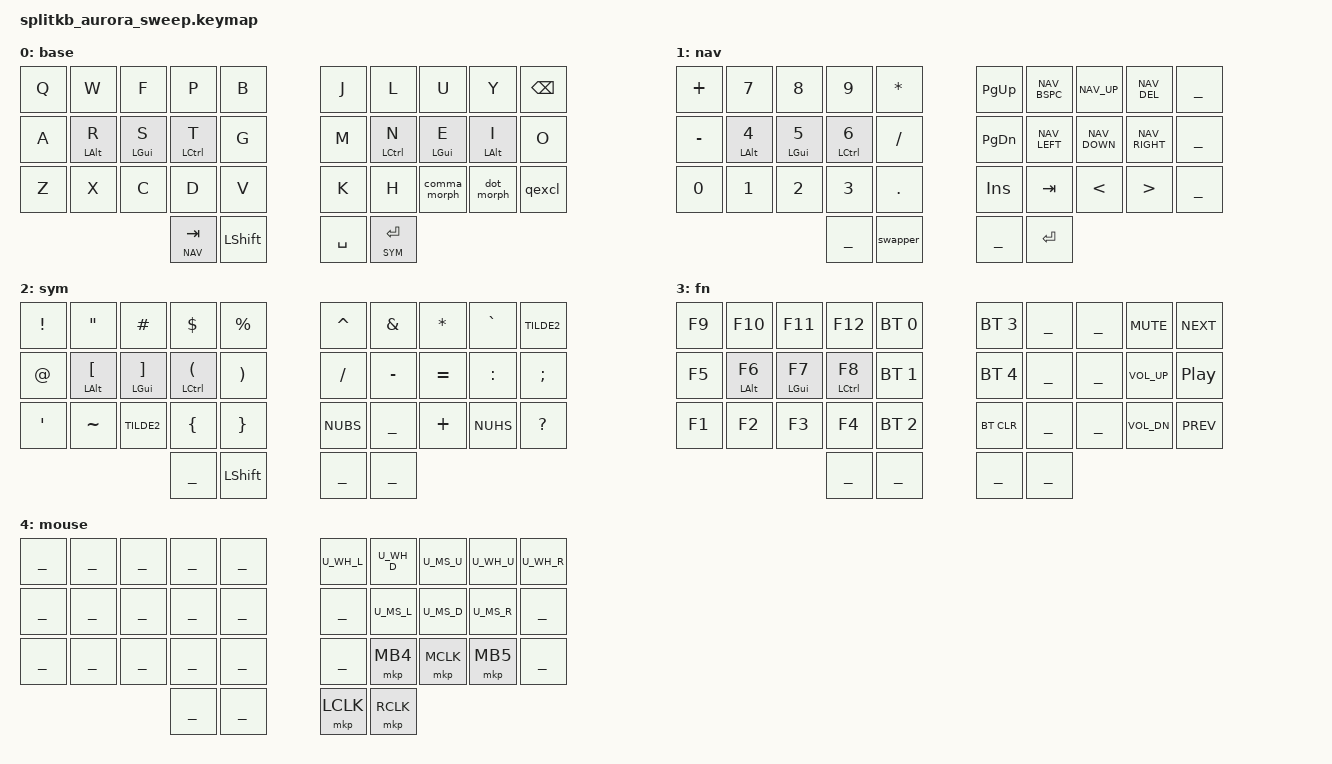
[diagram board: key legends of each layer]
/* source key position labels */
#include "zmk-helpers/key-labels/34.h"

/* source the main keymap */
#include "base.keymap"
ZMK_CONDITIONAL_LAYER(NAV SYM, FN)  // SYM + NAV --> FN

ZMK_LAYER(base,
//╭─────────────┬─────────────┬─────────────┬─────────────┬─────────────╮ ╭─────────────┬─────────────┬─────────────┬─────────────┬─────────────╮
    &kp Q         &kp W         &kp F         &kp P         &kp B           &kp J         &kp L         &kp U         &kp Y         &kp BSPC
//├─────────────┼─────────────┼─────────────┼─────────────┼─────────────┤ ├─────────────┼─────────────┼─────────────┼─────────────┼─────────────┤
    &kp A         &hml LALT R   &hml LGUI S   &hml LCTRL T  &kp G           &kp M         &hmr LCTRL N  &hmr LGUI E   &hmr LALT I   &kp O
//├─────────────┼─────────────┼─────────────┼─────────────┼─────────────┤ ├─────────────┼─────────────┼─────────────┼─────────────┼─────────────┤
    &kp Z         &kp X         &kp C         &kp D         &kp V           &kp K         &kp H         &comma_morph  &dot_morph    &qexcl
//╰─────────────┼─────────────┴─────────────┼─────────────┼─────────────┤ ├─────────────┼─────────────┼─────────────┴───────────────────────────╯
                                              &lt NAV TAB   &kp LSHIFT      &kp SPACE     &lt SYM RET
//                                          ╰─────────────┴─────────────╯ ╰─────────────┴─────────────╯
)

ZMK_LAYER(nav,
//╭─────────────┬─────────────┬─────────────┬─────────────┬─────────────╮ ╭─────────────┬─────────────┬─────────────┬─────────────┬─────────────╮
    &kp PLUS      &kp N7        &kp N8        &kp N9        &kp ASTRK       &kp PG_UP     NAV_BSPC      NAV_UP        NAV_DEL       ___
//├─────────────┼─────────────┼─────────────┼─────────────┼─────────────┤ ├─────────────┼─────────────┼─────────────┼─────────────┼─────────────┤
    &kp MINUS     &hml LALT N4  &hml LGUI N5  &hml LCTRL N6 &kp FSLH        &kp PG_DN     NAV_LEFT      NAV_DOWN      NAV_RIGHT     ___
//├─────────────┼─────────────┼─────────────┼─────────────┼─────────────┤ ├─────────────┼─────────────┼─────────────┼─────────────┼─────────────┤
    &kp N0        &kp N1        &kp N2        &kp N3        &kp DOT         &kp INS       &kp TAB       &kp LT        &kp GT        ___
//╰─────────────┼─────────────┴─────────────┼─────────────┼─────────────┤ ├─────────────┼─────────────┼─────────────┴───────────────────────────╯
                                              ___           &swapper        ___           &kp RET
//                                          ╰─────────────┴─────────────╯ ╰─────────────┴─────────────╯
)

ZMK_LAYER(sym,
//╭─────────────┬─────────────┬─────────────┬─────────────┬─────────────╮ ╭─────────────┬─────────────┬─────────────┬─────────────┬─────────────╮
    &kp EXCL      &kp DQT       &kp HASH      &kp DLLR      &kp PRCNT       &kp CARET     &kp AMPS      &kp ASTRK     &kp GRAVE     &kp TILDE2
//├─────────────┼─────────────┼─────────────┼─────────────┼─────────────┤ ├─────────────┼─────────────┼─────────────┼─────────────┼─────────────┤
    &kp AT        &hml LALT LBKT &hml LGUI RBKT &hml LCTRL LPAR &kp RPAR    &kp FSLH      &kp MINUS     &kp EQUAL     &kp COLON     &kp SEMI
//├─────────────┼─────────────┼─────────────┼─────────────┼─────────────┤ ├─────────────┼─────────────┼─────────────┼─────────────┼─────────────┤
    &kp SQT       &kp TILDE      &kp TILDE2   &kp LBRC      &kp RBRC        &kp NUBS      &kp UNDER     &kp PLUS      &kp NUHS      &kp QMARK
//╰─────────────┼─────────────┴─────────────┼─────────────┼─────────────┤ ├─────────────┼─────────────┼─────────────┴───────────────────────────╯
                                              ___           &kp LSHIFT      ___           ___
//                                          ╰─────────────┴─────────────╯ ╰─────────────┴─────────────╯
)

ZMK_LAYER(fn,
//╭─────────────┬─────────────┬─────────────┬─────────────┬─────────────╮ ╭─────────────┬─────────────┬─────────────┬─────────────┬─────────────╮
   &kp F9        &kp F10       &kp F11       &kp F12       &bt BT_SEL 0     &bt BT_SEL 3  ___           ___           &kp C_MUTE    &kp C_NEXT
//├─────────────┼─────────────┼─────────────┼─────────────┼─────────────┤ ├─────────────┼─────────────┼─────────────┼─────────────┼─────────────┤
   &kp F5        &hml LALT F6  &hml LGUI F7  &hml LCTRL F8 &bt BT_SEL 1     &bt BT_SEL 4  ___           ___           &kp C_VOL_UP  &kp C_PP
//├─────────────┼─────────────┼─────────────┼─────────────┼─────────────┤ ├─────────────┼─────────────┼─────────────┼─────────────┼─────────────┤
   &kp F1        &kp F2        &kp F3        &kp F4        &bt BT_SEL 2     &bt BT_CLR    ___           ___           &kp C_VOL_DN  &kp C_PREV
//╰─────────────┼─────────────┴─────────────┼─────────────┼─────────────┤ ├─────────────┼─────────────┼─────────────┴───────────────────────────╯
                                              ___           ___             ___           ___
//                                          ╰─────────────┴─────────────╯ ╰─────────────┴─────────────╯
)

ZMK_LAYER(mouse,
//╭─────────────┬─────────────┬─────────────┬─────────────┬─────────────╮ ╭─────────────┬─────────────┬─────────────┬─────────────┬─────────────╮
    ___           ___           ___           ___           ___             U_WH_L        U_WH_D        U_MS_U         U_WH_U       U_WH_R
//├─────────────┼─────────────┼─────────────┼─────────────┼─────────────┤ ├─────────────┼─────────────┼─────────────┼─────────────┼─────────────┤
    ___           ___           ___           ___           ___             ___           U_MS_L        U_MS_D         U_MS_R       ___
//├─────────────┼─────────────┼─────────────┼─────────────┼─────────────┤ ├─────────────┼─────────────┼─────────────┼─────────────┼─────────────┤
    ___           ___           ___           ___           ___             ___           &mkp MB4      &mkp MCLK      &mkp MB5     ___
//╰─────────────┼─────────────┴─────────────┼─────────────┼─────────────┤ ├─────────────┼─────────────┼─────────────┴───────────────────────────╯
                                              ___           ___             &mkp LCLK     &mkp RCLK
//                                          ╰─────────────┴─────────────╯ ╰─────────────┴─────────────╯
)
